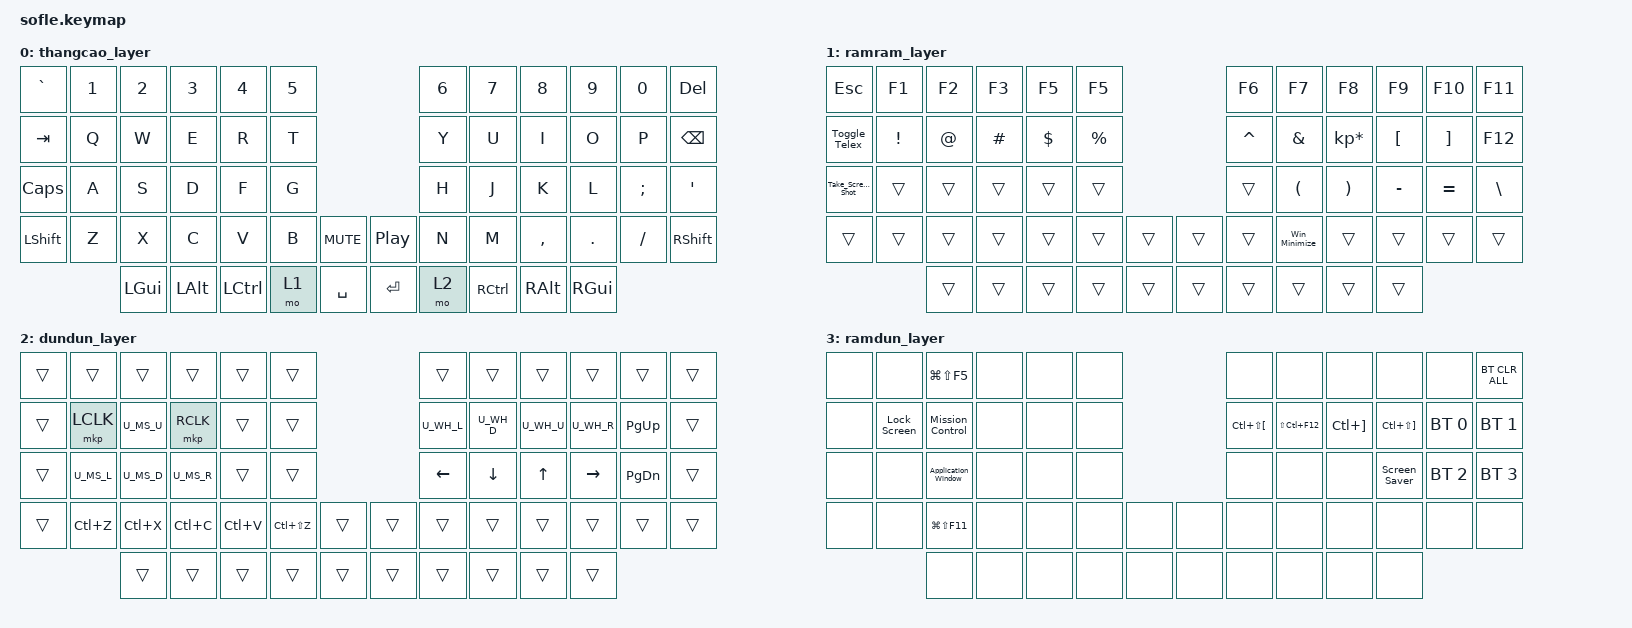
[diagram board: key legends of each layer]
/*
 * Copyright (c) 2020 The ZMK Contributors
 *
 * SPDX-License-Identifier: MIT
 */

#include <behaviors.dtsi>
#include <dt-bindings/zmk/bt.h>
#include <dt-bindings/zmk/keys.h>
#include "mouse.dtsi" 

#define THANGCAO 0
#define RAMRAM 1
#define DUNDUN 2
#define RAMDUN 3

/ {
    // Activate RamDun layer by pressing DunDun and RamRam

    conditional_layers {
        compatible = "zmk,conditional-layers";

        ramdun_layer {
            if-layers = <RAMRAM DUNDUN>;
            then-layer = <RAMDUN>;
        };
    };

    macros {
        Toggle_Telex: Toggle_Telex {
            compatible = "zmk,behavior-macro";
            #binding-cells = <0>;
            bindings = <&kp LA(Z)>;
        };

        Take_Screen_Shot: Take_Screen_Shot {
            compatible = "zmk,behavior-macro";
            #binding-cells = <0>;
            bindings = <&kp LC(LS(LG(NUMBER_4)))>;
        };

        Screen_Saver: Screen_Saver {
            compatible = "zmk,behavior-macro";
            #binding-cells = <0>;
            bindings = <&kp LS(LC(LG(L)))>;
        };

        Mission_Control: Mission_Control {
            compatible = "zmk,behavior-macro";
            #binding-cells = <0>;
            bindings = <&kp LA(UP_ARROW)>;
        };

        Application_Window: Application_Window {
            compatible = "zmk,behavior-macro";
            #binding-cells = <0>;
            bindings = <&kp LA(DOWN)>;
        };

        Lock_Screen: Lock_Screen {
            compatible = "zmk,behavior-macro";
            #binding-cells = <0>;
            bindings = <&kp LC(LG(Q))>;
        };

        Win_Minimize: win_minimize {
            compatible = "zmk,behavior-macro";
            #binding-cells = <0>;
            bindings = <&kp LG(DOWN_ARROW)>;
        };
    };

    keymap {
        compatible = "zmk,keymap";

        thangcao_layer {

            // ------------------------------------------------------------------------------------------------------------
            // |   `   |  1  |  2  |  3   |  4   |  5   |                   |  6   |  7    |  8    |  9   |   0   |       |
            // |  ESC  |  Q  |  W  |  E   |  R   |  T   |                   |  Y   |  U    |  I    |  O   |   P   | BKSPC |
            // |  TAB  |  A  |  S  |  D   |  F   |  G   |                   |  H   |  J    |  K    |  L   |   ;   |   '   |
            // | SHIFT |  Z  |  X  |  C   |  V   |  B   |  MUTE  |  |       |  N   |  M    |  ,    |  .   |   /   | SHIFT |
            //               | GUI | ALT  | CTRL | LOWER|  ENTER |  | SPACE | RAISE| CTRL  | ALT   | GUI  |

            bindings = <
&kp GRAVE     &kp N1  &kp N2        &kp N3    &kp N4            &kp N5                                  &kp N6  &kp N7             &kp N8     &kp N9         &kp N0    &kp DELETE
&kp TAB       &kp Q   &kp W         &kp E     &kp R             &kp T                                   &kp Y   &kp U              &kp I      &kp O          &kp P     &kp BSPC
&kp CAPSLOCK  &kp A   &kp S         &kp D     &kp F             &kp G                                   &kp H   &kp J              &kp K      &kp L          &kp SEMI  &kp SQT
&kp LSHFT     &kp Z   &kp X         &kp C     &kp V             &kp B   &kp C_MUTE    &kp C_PLAY_PAUSE  &kp N   &kp M              &kp COMMA  &kp DOT        &kp FSLH  &kp RSHFT
                      &kp LEFT_GUI  &kp LALT  &kp LEFT_CONTROL  &mo 1   &kp SPACE     &kp ENTER         &mo 2   &kp RIGHT_CONTROL  &kp RALT   &kp RIGHT_GUI
            >;

            sensor-bindings =
                <&inc_dec_kp C_VOLUME_DOWN C_VOLUME_UP>,
                <&inc_dec_kp PG_UP PG_DN>;
        };

        ramram_layer {

            // TODO: Some binds are waiting for shifted keycode support.
            // ------------------------------------------------------------------------------------------------------------
            // |       |  F1 |  F2 |  F3  |  F4  |  F5  |                   |  F6  |  F7   |  F8   |  F9  |  F10  |  F11  |
            // |   `   |  1  |  2  |  3   |  4   |  5   |                   |  6   |  7    |  8    |  9   |   0   |  F12  |
            // |       |  !  |  @  |  #   |  $   |  %   |                   |  ^   |  &    |  *    |  (   |   )   |   |   |
            // |       |  =  |  -  |  +   |  {   |  }   |        |  |       |  [   |  ]    |  ;    |  :   |   \   |       |
            //               |     |      |      |      |        |  |       |      |       |       |      |

            bindings = <
&kp ESCAPE         &kp F1           &kp F2       &kp F3    &kp F5      &kp F5                         &kp F6     &kp F7                &kp F8                 &kp F9            &kp F10            &kp F11
&Toggle_Telex      &kp EXCLAMATION  &kp AT_SIGN  &kp HASH  &kp DOLLAR  &kp PERCENT                    &kp CARET  &kp AMPERSAND         &kp KP_MULTIPLY        &kp LEFT_BRACKET  &kp RIGHT_BRACKET  &kp F12
&Take_Screen_Shot  &trans           &trans       &trans    &trans      &trans                         &trans     &kp LEFT_PARENTHESIS  &kp RIGHT_PARENTHESIS  &kp MINUS         &kp EQUAL          &kp BACKSLASH
&trans             &trans           &trans       &trans    &trans      &trans       &trans    &trans  &trans     &Win_Minimize         &trans                 &trans            &trans             &trans
                                    &trans       &trans    &trans      &trans       &trans    &trans  &trans     &trans                &trans                 &trans
            >;

            sensor-bindings =
                <&inc_dec_kp C_VOLUME_DOWN C_VOLUME_UP>,
                <&inc_dec_kp C_PREVIOUS C_NEXT>;
        };

        dundun_layer {

            // ------------------------------------------------------------------------------------------------------------
            // | BTCLR | BT1  | BT2  |  BT3  |  BT4  |  BT5 |                |      |      |       |      |       |       |
            // |       | INS  | PSCR | GUI   |       |      |                | PGUP |      |   ^   |      |       |       |
            // |       | ALT  | CTRL | SHIFT |       | CAPS |                | PGDN |   <- |   v   |  ->  |  DEL  | BKSPC |
            // |       | UNDO | CUT  | COPY  | PASTE |      |      |  |      |      |      |       |      |       |       |
            //                |      |       |       |      |      |  |      |      |      |       |      |

            bindings = <
&trans  &trans          &trans          &trans           &trans       &trans                        &trans          &trans          &trans        &trans           &trans         &trans
&trans  &mkp LCLK       U_MS_U          &mkp RCLK        &trans       &trans                        U_WH_L          U_WH_D          U_WH_U        U_WH_R           &kp PAGE_UP    &trans
&trans  U_MS_L          U_MS_D          U_MS_R           &trans       &trans                        &kp LEFT_ARROW  &kp DOWN_ARROW  &kp UP_ARROW  &kp RIGHT        &kp PAGE_DOWN  &trans
&trans  &kp LC(Z)       &kp LC(X)       &kp LC(C)        &kp LC(V)    &kp LC(LS(Z)) &trans  &trans  &trans          &trans          &trans        &trans           &trans         &trans
                        &trans          &trans           &trans       &trans        &trans  &trans  &trans          &trans          &trans        &trans
            >;

            sensor-bindings =
                <&inc_dec_kp C_VOLUME_DOWN C_VOLUME_UP>,
                <&inc_dec_kp F14 F15>;
        };

        ramdun_layer {
            // ----------------------------------------------------------------------------------------------------------------------------
            // | BTCLR  |  BT1    |  BT2    |   BT3   |   BT4   |   BT5   |                  |      |      |       |      |       |       |
            // | EXTPWR | RGB_HUD | RGB_HUI | RGB_SAD | RGB_SAI | RGB_EFF |                  |      |      |       |      |       |       |
            // |        | RGB_BRD | RGB_BRI |         |         |         |                  |      |      |       |      |       |       |
            // |        |         |         |         |         |         | RGB_TOG | |      |      |      |       |      |       |       |
            //                    |         |         |         |         |         | |      |      |      |       |      |

            bindings = <
&none  &none               &kp LG(LS(F5))       &none                &none  &none                  &none                     &none            &none                  &none                      &none         &bt BT_CLR_ALL
&none  &Lock_Screen        &Mission_Control     &none                &none  &none                  &kp LC(LS(LEFT_BRACKET))  &kp LS(LC(F12))  &kp LC(RIGHT_BRACKET)  &kp LC(LS(RIGHT_BRACKET))  &bt BT_SEL 0  &bt BT_SEL 1
&none  &none               &Application_Window  &none                &none  &none                  &none                     &none            &none                  &Screen_Saver              &bt BT_SEL 2  &bt BT_SEL 3
&none  &none               &kp LG(LS(F11))      &none                &none  &none  &none    &none  &none                     &none            &none                  &none                      &none         &none
                           &none                &none                &none  &none  &none    &none  &none                     &none            &none                  &none
            >;
        };
    };
};
